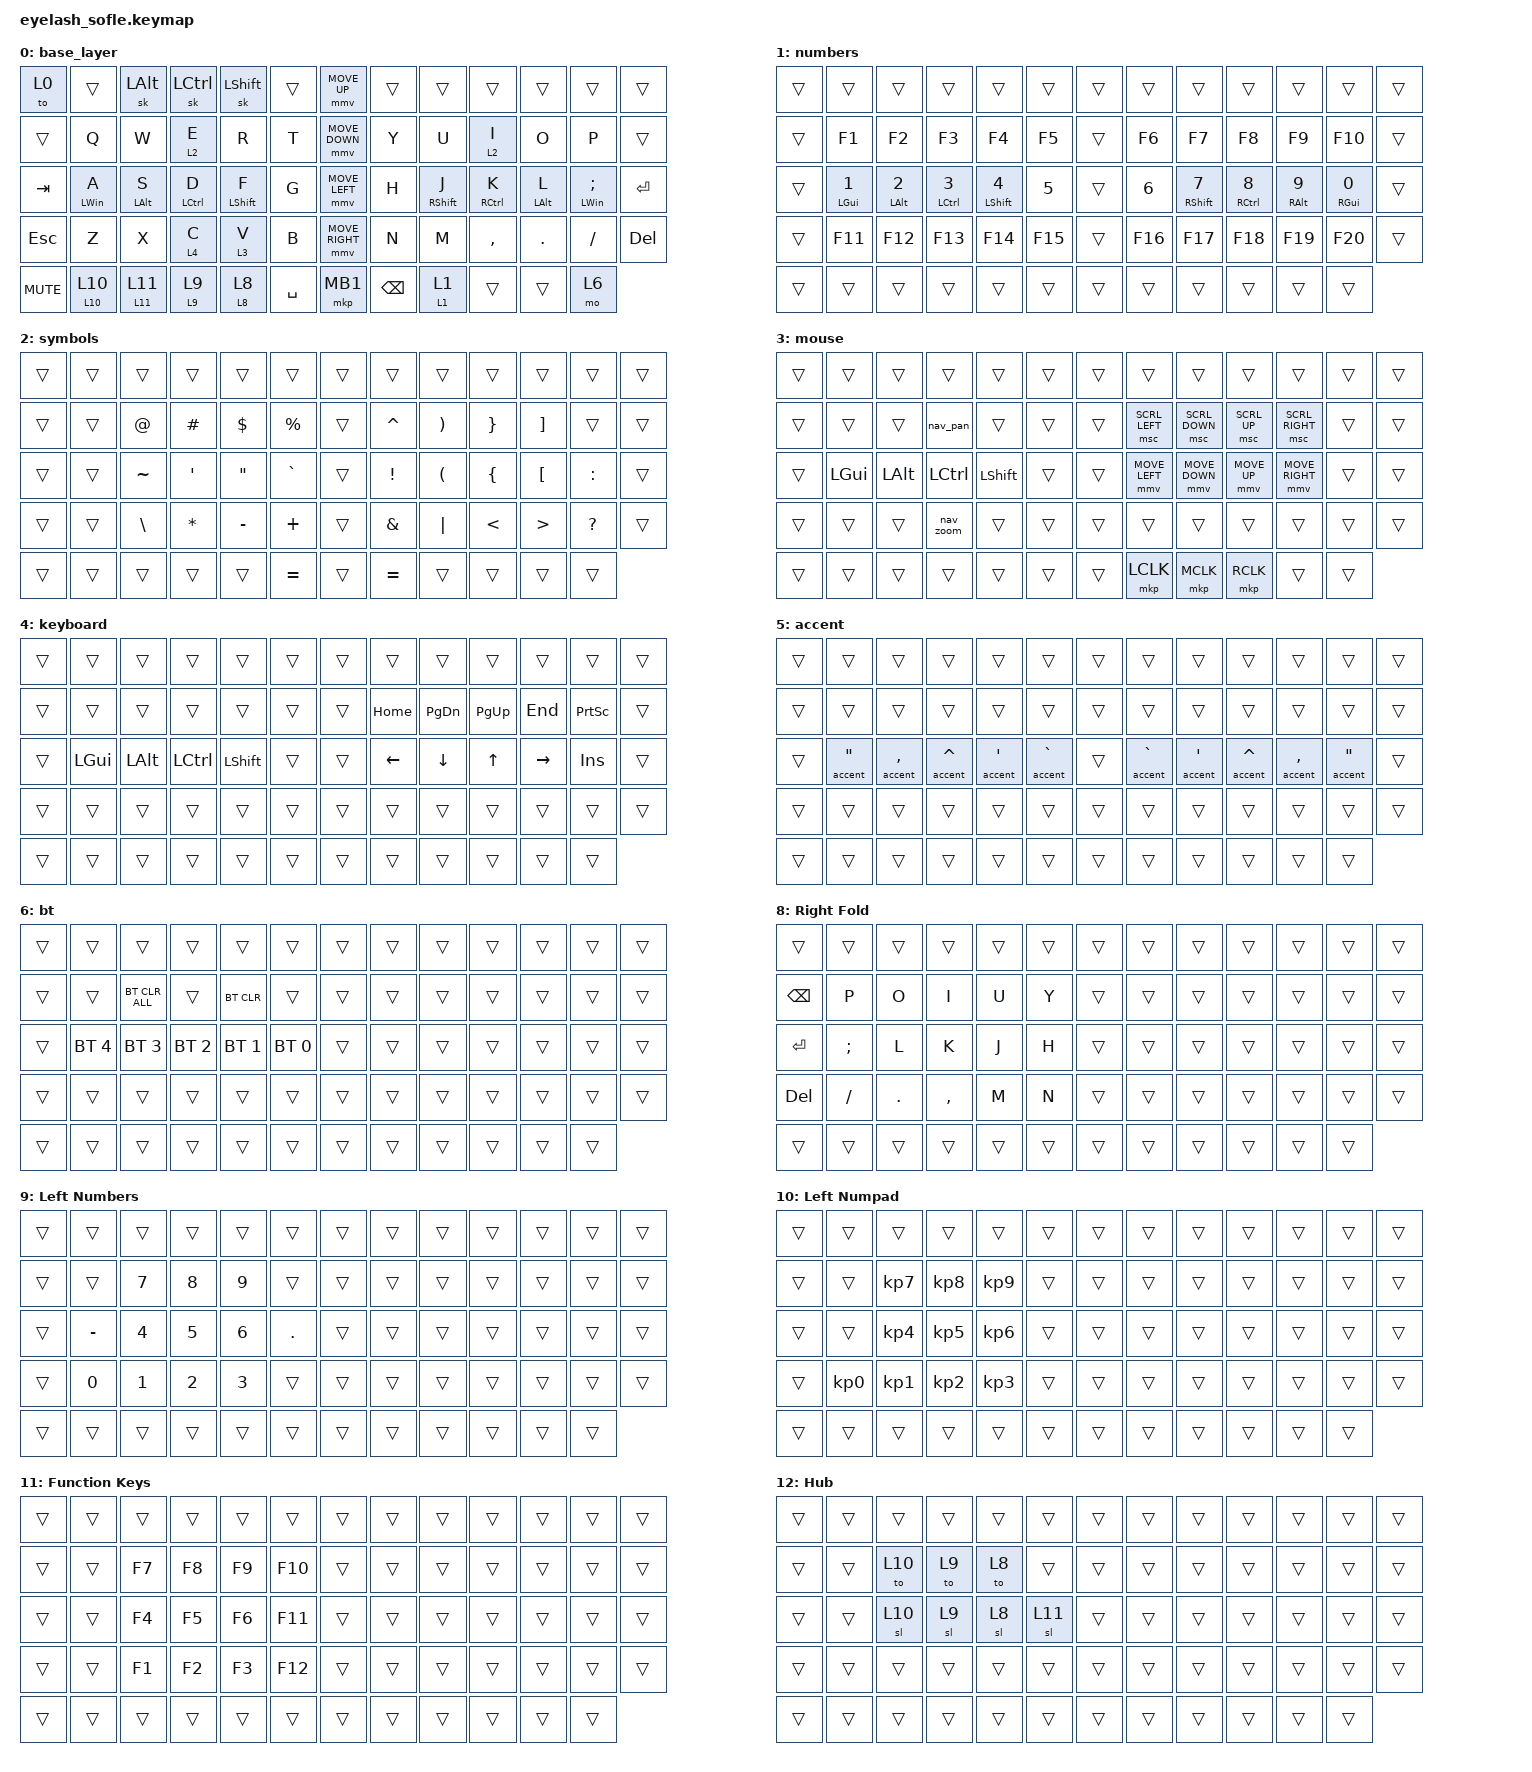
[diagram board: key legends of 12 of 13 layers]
#define ZMK_POINTING_DEFAULT_MOVE_VAL 1200  // 600
#define ZMK_POINTING_DEFAULT_SCRL_VAL 25   // 10

#include <input/processors.dtsi>
#include <zephyr/dt-bindings/input/input-event-codes.h>
#include <behaviors.dtsi>
#include <dt-bindings/zmk/bt.h>
#include <dt-bindings/zmk/keys.h>
#include <dt-bindings/zmk/pointing.h>

&mmv_input_listener { input-processors = <&zip_xy_scaler 2 1>; };

&msc_input_listener { input-processors = <&zip_scroll_scaler 2 1>; };

&msc {
    acceleration-exponent = <1>;      // 0
    time-to-max-speed-ms = <100>;       // 300
    delay-ms = <0>;                   // 0
};

&mmv {
    time-to-max-speed-ms = <500>;
    acceleration-exponent = <1>;
    trigger-period-ms = <16>;
};

&soft_off { hold-time-ms = <2000>; };

/ {
    scroll_encoder: scroll_encoder {
        compatible = "zmk,behavior-sensor-rotate";
        #sensor-binding-cells = <0>;
        bindings = <&msc SCRL_DOWN>, <&msc SCRL_UP>;

        tap-ms = <100>;
    };

    period: period {
        compatible = "zmk,behavior-tap-dance";
        label = "PERIOD";
        #binding-cells = <0>;
        bindings = <&mt EXCL PERIOD>, <&mt QUESTION COLON>;
    };

    period_plus: period_plus {
        compatible = "zmk,behavior-tap-dance";
        label = "PERIOD_PLUS";
        #binding-cells = <0>;
        bindings = <&kp EXCL>, <&kp QMARK>;
    };

    comma: comma {
        compatible = "zmk,behavior-tap-dance";
        label = "COMMA";
        #binding-cells = <0>;
        bindings = <&kp COMMA>, <&kp SEMI>;
    };

    quote: quote {
        compatible = "zmk,behavior-tap-dance";
        label = "QUOTE";
        #binding-cells = <0>;
        bindings = <&mt GRAVE SQT>, <&kp DOUBLE_QUOTES>;
    };

    division: division {
        compatible = "zmk,behavior-tap-dance";
        label = "DIVISION";
        #binding-cells = <0>;
        bindings = <&kp SLASH>, <&kp PERCENT>;
    };

    group_begin: group_begin {
        compatible = "zmk,behavior-tap-dance";
        label = "GROUP_BEGIN";
        #binding-cells = <0>;
        bindings = <&kp LPAR>, <&kp LBKT>, <&kp LBRC>;
    };

    group_end: group_end {
        compatible = "zmk,behavior-tap-dance";
        label = "GROUP_END";
        #binding-cells = <0>;
        bindings = <&kp RPAR>, <&kp RBKT>, <&kp RBRC>;
    };

    encoder_page: encoder_page {
        compatible = "zmk,behavior-sensor-rotate";
        label = "ENCODER_PAGE";
        #sensor-binding-cells = <0>;
        bindings = <&kp PAGE_DOWN>, <&kp PAGE_UP>;
    };

    bt_nav: bt_nav {
        compatible = "zmk,behavior-sensor-rotate";
        label = "BT_NAV";
        #sensor-binding-cells = <0>;
        bindings = <&bt BT_NXT>, <&bt BT_NXT>;
    };

    mouse_mode: mouse_mode {
        compatible = "zmk,behavior-tap-dance";
        label = "MOUSE_MODE";
        #binding-cells = <0>;
        bindings = <&kp M>, <&to 0>;
    };

    keyboard_mode: keyboard_mode {
        compatible = "zmk,behavior-tap-dance";
        label = "KEYBOARD_MODE";
        #binding-cells = <0>;
        bindings = <&kp V>, <&to 0>;
    };

    home_row_mod: home_row_mod {
        compatible = "zmk,behavior-hold-tap";
        label = "HOME_ROW_MOD";
        bindings = <&kp>, <&kp>;

        #binding-cells = <2>;
        tapping-term-ms = <300>;
        flavor = "balanced";
    };

    tap_hold_kp: tap_hold_kp {
        compatible = "zmk,behavior-hold-tap";
        label = "TAP_HOLD_KP";
        bindings = <&kp>, <&kp>;

        #binding-cells = <2>;
        flavor = "tap-preferred";
        tapping-term-ms = <200>;
    };

    sl_or_mo: sl_or_mo {
        compatible = "zmk,behavior-hold-tap";
        label = "SL_OR_MO";
        bindings = <&mo>, <&sl>;

        #binding-cells = <2>;
        tapping-term-ms = <200>;
        flavor = "balanced";
    };

    symbol_layer_access: symbol_layer_access {
        compatible = "zmk,behavior-tap-dance";
        label = "SYMBOL_LAYER_ACCESS";
        #binding-cells = <0>;
        bindings = <&sl_or_mo 0 0>, <&to 0>;
    };

    cedilla_trema: cedilla_trema {
        compatible = "zmk,behavior-hold-tap";
        label = "CEDILLA_TREMA";
        bindings = <&accent>, <&accent>;

        #binding-cells = <2>;
        tapping-term-ms = <200>;
        flavor = "tap-preferred";
    };

    left_hand_dance: left_hand_dance {
        compatible = "zmk,behavior-tap-dance";
        label = "LEFT_HAND_DANCE";
        #binding-cells = <0>;
        bindings = <&mo 0>, <&mo 0>;

        tapping-term-ms = <250>;
    };

    mouse_numbers_dance: mouse_numbers_dance {
        compatible = "zmk,behavior-tap-dance";
        label = "MOUSE_NUMBERS_DANCE";
        #binding-cells = <0>;
        bindings = <&mo 0>, <&mo 0>, <&to 0>;

        tapping-term-ms = <250>;
    };

    caps_constant: caps_constant {
        compatible = "zmk,behavior-caps-word";
        label = "CAPS_CONSTANT";
        #binding-cells = <0>;
        continue-list = <Q W E R T Y U I O P A S D F G H J K L Z X C V B N M UNDERSCORE NUMBER_1 NUMBER_2 NUMBER_3 NUMBER_4 NUMBER_5 NUMBER_6 NUMBER_7 NUMBER_8 NUMBER_9 NUMBER_0 BACKSPACE>;
        mods = <(MOD_LSFT)>;
    };

    sl_to_mo: sl_to_mo {
        compatible = "zmk,behavior-hold-tap";
        label = "SL_TO_MO";
        bindings = <&mo>, <&sl>;

        #binding-cells = <2>;
        tapping-term-ms = <250>;
    };

    kp_or_sk: kp_or_sk {
        compatible = "zmk,behavior-hold-tap";
        label = "KP_OR_SK";
        bindings = <&kp>, <&sk>;

        #binding-cells = <2>;
        tapping-term-ms = <300>;
        flavor = "balanced";
    };

    behaviors {
    };

    combos {
        compatible = "zmk,combos";

        softoff {
            bindings = <&soft_off>;
            key-positions = <14 28 40>;
        };

        combo_accent {
            bindings = <&sl 5>;
            key-positions = <57 59>;
        };

        combo_repeat {
            bindings = <&key_repeat>;
            key-positions = <17 16>;
        };

        combo_mouse_mode {
            bindings = <&to 3>;
            key-positions = <47 48>;
        };

        combo_keyboard_mode {
            bindings = <&to 4>;
            key-positions = <48 49>;
        };

        combo_constant {
            bindings = <&caps_constant>;
            key-positions = <22 23>;
        };

        combo_underscore {
            bindings = <&kp UNDER>;
            key-positions = <21 22>;
        };

        reset {
            bindings = <&to 0>;
            key-positions = <28 29>;
        };

        shift_ctrl {
            bindings = <&sk LS(LCTRL)>;
            key-positions = <4 3>;
        };

        shift_alt {
            bindings = <&sk LS(LEFT_ALT)>;
            key-positions = <4 2>;
        };

        ctrl_alt {
            bindings = <&sk LC(LEFT_ALT)>;
            key-positions = <3 2>;
        };

        shift_ctrl_alt {
            bindings = <&sk LS(LC(LALT))>;
            key-positions = <2 3 4>;
        };

        shift_ctrl_low {
            bindings = <&sk LS(LCTRL)>;
            key-positions = <55 54>;
        };

        shift_alt_low {
            bindings = <&sk LS(LEFT_ALT)>;
            key-positions = <53 55>;
        };

        ctrl_alt_low {
            bindings = <&sk LC(LEFT_ALT)>;
            key-positions = <53 54>;
        };

        shift_ctrl_alt_low {
            bindings = <&sk LS(LC(LALT))>;
            key-positions = <53 54 55>;
        };

        goto_hub {
            bindings = <&sl 12>;
            key-positions = <30 29>;
        };

        combo_constant_left {
            bindings = <&caps_constant>;
            key-positions = <16 15>;
        };
    };

    macros {
        nav_pan: lclk_ctrl {
            compatible = "zmk,behavior-macro";
            #binding-cells = <0>;
            bindings =
                <&macro_press>,
                <&kp LSHFT &mkp MCLK>,
                <&macro_pause_for_release>,
                <&macro_release>,
                <&mkp MCLK &kp LSHFT>;

            label = "LCLK_CTRL";
        };

        nav_zoom: nav_zoom {
            compatible = "zmk,behavior-macro";
            #binding-cells = <0>;
            bindings =
                <&macro_press>,
                <&kp LCTRL &mkp MCLK>,
                <&macro_pause_for_release>,
                <&macro_release>,
                <&mkp MCLK &kp LCTRL>;

            label = "NAV_ZOOM";
        };

        ml_shift: ml_shift {
            compatible = "zmk,behavior-macro";
            #binding-cells = <0>;
            bindings =
                <&macro_press>,
                <&kp LSHFT &mkp LCLK>,
                <&macro_pause_for_release>,
                <&macro_release>,
                <&mkp LCLK &kp LSHFT>;

            label = "ML_SHIFT";
        };

        ml_ctrl: ml_ctrl {
            compatible = "zmk,behavior-macro";
            #binding-cells = <0>;
            bindings =
                <&macro_press>,
                <&kp LCTRL &mkp LCLK>,
                <&macro_pause_for_release>,
                <&macro_release>,
                <&mkp LCLK &kp LCTRL>;

            label = "ML_CTRL";
        };

        ml_alt: ml_alt {
            compatible = "zmk,behavior-macro";
            #binding-cells = <0>;
            bindings =
                <&macro_press>,
                <&kp LALT &mkp LCLK>,
                <&macro_pause_for_release>,
                <&macro_release>,
                <&mkp LCLK &kp LALT>;

            label = "ML_ALT";
        };

        accent: grave_accent {
            compatible = "zmk,behavior-macro-one-param";
            #binding-cells = <1>;
            bindings = <&kp CAPSLOCK &macro_param_1to1 &kp MACRO_PLACEHOLDER>;
            label = "GRAVE_ACCENT";
        };

        new_macro: new_macro {
            compatible = "zmk,behavior-macro-one-param";
            #binding-cells = <1>;
            bindings = <&macro_param_1to1 &sk MACRO_PLACEHOLDER &sl 8>;
            label = "NEW_MACRO";
        };
    };

    keymap {
        compatible = "zmk,keymap";

        base_layer {
            bindings = <
&to 0       &trans                &sk LEFT_ALT          &sk LCTRL              &sk LEFT_SHIFT         &trans       &mmv MOVE_UP     &trans         &trans                  &trans                 &trans                &trans                        &trans
&trans      &kp Q                 &kp W                 &lt 2 E                &kp R                  &kp T        &mmv MOVE_DOWN   &kp Y          &kp U                   &lt 2 I                &kp O                 &kp P                         &trans
&kp TAB     &home_row_mod LWIN A  &home_row_mod LALT S  &home_row_mod LCTRL D  &home_row_mod LSHFT F  &kp G        &mmv MOVE_LEFT   &kp H          &home_row_mod RSHIFT J  &home_row_mod RCTRL K  &home_row_mod LALT L  &home_row_mod LWIN SEMICOLON  &kp ENTER
&kp ESCAPE  &kp Z                 &kp X                 &lt 4 C                &lt 3 V                &kp B        &mmv MOVE_RIGHT  &kp N          &kp M                   &kp COMMA              &kp PERIOD            &kp SLASH                     &kp DELETE
&kp C_MUTE  &sl_or_mo 10 10       &sl_to_mo 11 11       &sl_or_mo 9 9          &sl_or_mo 8 8          &kp SPACE    &mkp MB1         &kp BACKSPACE  &sl_to_mo 1 1           &trans                 &trans                &mo 6
            >;

            display-name = "base_layer";
            sensor-bindings = <&inc_dec_kp PAGE_DOWN PAGE_UP>;
        };

        numbers {
            bindings = <
&trans  &trans                 &trans                 &trans                  &trans                  &trans     &trans  &trans   &trans                  &trans                  &trans                 &trans                 &trans
&trans  &kp F1                 &kp F2                 &kp F3                  &kp F4                  &kp F5     &trans  &kp F6   &kp F7                  &kp F8                  &kp F9                 &kp F10                &trans
&trans  &home_row_mod LGUI N1  &home_row_mod LALT N2  &home_row_mod LCTRL N3  &home_row_mod LSHFT N4  &kp N5     &trans  &kp N6   &home_row_mod RSHFT N7  &home_row_mod RCTRL N8  &home_row_mod RALT N9  &home_row_mod RGUI N0  &trans
&trans  &kp F11                &kp F12                &kp F13                 &kp F14                 &kp F15    &trans  &kp F16  &kp F17                 &kp F18                 &kp F19                &kp F20                &trans
&trans  &trans                 &trans                 &trans                  &trans                  &trans     &trans  &trans   &trans                  &trans                  &trans                 &trans
            >;

            label = "numbers";
        };

        symbols {
            label = "symbols";
            bindings = <
&trans  &trans  &trans         &trans    &trans      &trans         &trans  &trans           &trans    &trans    &trans    &trans        &trans
&trans  &trans  &kp AT         &kp HASH  &kp DOLLAR  &kp PERCENT    &trans  &kp CARET        &kp RPAR  &kp RBRC  &kp RBKT  &trans        &trans
&trans  &trans  &kp TILDE      &kp SQT   &kp DQT     &kp GRAVE      &trans  &kp EXCLAMATION  &kp LPAR  &kp LBRC  &kp LBKT  &kp COLON     &trans
&trans  &trans  &kp BACKSLASH  &kp STAR  &kp MINUS   &kp PLUS       &trans  &kp AMPS         &kp PIPE  &kp LT    &kp GT    &kp QUESTION  &trans
&trans  &trans  &trans         &trans    &trans      &kp EQUAL      &trans  &kp EQUAL        &trans    &trans    &trans    &trans
            >;
        };

        mouse {
            bindings = <
&trans  &trans    &trans    &trans     &trans     &trans    &trans  &trans          &trans          &trans        &trans           &trans  &trans
&trans  &trans    &trans    &nav_pan   &trans     &trans    &trans  &msc SCRL_LEFT  &msc SCRL_DOWN  &msc SCRL_UP  &msc SCRL_RIGHT  &trans  &trans
&trans  &kp LGUI  &kp LALT  &kp LCTRL  &kp LSHFT  &trans    &trans  &mmv MOVE_LEFT  &mmv MOVE_DOWN  &mmv MOVE_UP  &mmv MOVE_RIGHT  &trans  &trans
&trans  &trans    &trans    &nav_zoom  &trans     &trans    &trans  &trans          &trans          &trans        &trans           &trans  &trans
&trans  &trans    &trans    &trans     &trans     &trans    &trans  &mkp LCLK       &mkp MCLK       &mkp RCLK     &trans           &trans
            >;

            label = "mouse";
        };

        keyboard {
            bindings = <
&trans  &trans    &trans    &trans     &trans     &trans    &trans  &trans    &trans         &trans       &trans     &trans           &trans
&trans  &trans    &trans    &trans     &trans     &trans    &trans  &kp HOME  &kp PAGE_DOWN  &kp PAGE_UP  &kp END    &kp PRINTSCREEN  &trans
&trans  &kp LGUI  &kp LALT  &kp LCTRL  &kp LSHFT  &trans    &trans  &kp LEFT  &kp DOWN       &kp UP       &kp RIGHT  &kp INSERT       &trans
&trans  &trans    &trans    &trans     &trans     &trans    &trans  &trans    &trans         &trans       &trans     &trans           &trans
&trans  &trans    &trans    &trans     &trans     &trans    &trans  &trans    &trans         &trans       &trans     &trans
            >;

            label = "keyboard";
        };

        accent {
            bindings = <
&trans  &trans                 &trans         &trans         &trans       &trans           &trans  &trans         &trans        &trans         &trans         &trans                 &trans
&trans  &trans                 &trans         &trans         &trans       &trans           &trans  &trans         &trans        &trans         &trans         &trans                 &trans
&trans  &accent DOUBLE_QUOTES  &accent COMMA  &accent CARET  &accent SQT  &accent GRAVE    &trans  &accent GRAVE  &accent APOS  &accent CARET  &accent COMMA  &accent DOUBLE_QUOTES  &trans
&trans  &trans                 &trans         &trans         &trans       &trans           &trans  &trans         &trans        &trans         &trans         &trans                 &trans
&trans  &trans                 &trans         &trans         &trans       &trans           &trans  &trans         &trans        &trans         &trans         &trans
            >;

            label = "accent";
        };

        bt {
            bindings = <
&trans  &trans        &trans          &trans        &trans        &trans          &trans  &trans  &trans  &trans  &trans  &trans  &trans
&trans  &trans        &bt BT_CLR_ALL  &trans        &bt BT_CLR    &trans          &trans  &trans  &trans  &trans  &trans  &trans  &trans
&trans  &bt BT_SEL 4  &bt BT_SEL 3    &bt BT_SEL 2  &bt BT_SEL 1  &bt BT_SEL 0    &trans  &trans  &trans  &trans  &trans  &trans  &trans
&trans  &trans        &trans          &trans        &trans        &trans          &trans  &trans  &trans  &trans  &trans  &trans  &trans
&trans  &trans        &trans          &trans        &trans        &trans          &trans  &trans  &trans  &trans  &trans  &trans
            >;

            label = "bt";
        };

        shortcut {
            bindings = <
&trans  &trans                 &trans                 &trans                 &trans                 &trans                   &trans  &trans                 &trans                 &trans                  &trans                  &trans                     &trans
&trans  &kp LS(LG(LC(LA(Q))))  &kp LS(LG(LC(LA(W))))  &kp LS(LG(LC(LA(E))))  &kp LS(LG(LC(LA(R))))  &kp LS(LG(LC(LA(T))))    &trans  &kp LS(LG(LC(LA(Y))))  &kp LS(LG(LC(LA(U))))  &kp LS(LG(LC(LA(I))))   &kp LS(LG(LC(LA(O))))   &kp LS(LG(LC(LA(P))))      &trans
&trans  &kp LS(LG(LC(LA(A))))  &kp LS(LG(LC(LA(S))))  &kp LS(LG(LC(LA(D))))  &kp LS(LG(LC(LA(F))))  &kp LS(LG(LC(LA(G))))    &trans  &kp LS(LG(LC(LA(H))))  &kp LS(LG(LC(LA(J))))  &kp LS(LG(LC(LA(K))))   &kp LS(LG(LC(LA(L))))   &kp LS(LG(LC(LA(COLON))))  &trans
&trans  &kp LS(LG(LC(LA(Z))))  &kp LS(LG(LC(LA(X))))  &kp LS(LG(LC(LA(C))))  &kp LS(LG(LC(LA(V))))  &kp LS(LG(LC(LA(B))))    &trans  &kp LS(LG(LC(LA(N))))  &kp LS(LG(LC(LA(M))))  &kp LS(LG(LC(LA(LT))))  &kp LS(LG(LC(LA(GT))))  &kp LS(LG(LC(LA(QMARK))))  &trans
&trans  &trans                 &trans                 &trans                 &trans                 &trans                   &trans  &trans                 &trans                 &trans                  &trans                  &trans
            >;

            label = "shortcut";
        };

        right_fold {
            bindings = <
&trans         &trans    &trans   &trans     &trans  &trans    &trans  &trans  &trans  &trans  &trans  &trans  &trans
&kp BACKSPACE  &kp P     &kp O    &kp I      &kp U   &kp Y     &trans  &trans  &trans  &trans  &trans  &trans  &trans
&kp ENTER      &kp SEMI  &kp L    &kp K      &kp J   &kp H     &trans  &trans  &trans  &trans  &trans  &trans  &trans
&kp DELETE     &kp FSLH  &kp DOT  &kp COMMA  &kp M   &kp N     &trans  &trans  &trans  &trans  &trans  &trans  &trans
&trans         &trans    &trans   &trans     &trans  &trans    &trans  &trans  &trans  &trans  &trans  &trans
            >;

            label = "Right Fold";
        };

        left_numbers {
            bindings = <
&trans  &trans     &trans  &trans  &trans  &trans        &trans  &trans  &trans  &trans  &trans  &trans  &trans
&trans  &trans     &kp N7  &kp N8  &kp N9  &trans        &trans  &trans  &trans  &trans  &trans  &trans  &trans
&trans  &kp MINUS  &kp N4  &kp N5  &kp N6  &kp PERIOD    &trans  &trans  &trans  &trans  &trans  &trans  &trans
&trans  &kp N0     &kp N1  &kp N2  &kp N3  &trans        &trans  &trans  &trans  &trans  &trans  &trans  &trans
&trans  &trans     &trans  &trans  &trans  &trans        &trans  &trans  &trans  &trans  &trans  &trans
            >;

            label = "Left Numbers";
        };

        left_numpad {
            bindings = <
&trans  &trans     &trans           &trans           &trans           &trans    &trans  &trans  &trans  &trans  &trans  &trans  &trans
&trans  &trans     &kp KP_NUMBER_7  &kp KP_NUMBER_8  &kp KP_NUMBER_9  &trans    &trans  &trans  &trans  &trans  &trans  &trans  &trans
&trans  &trans     &kp KP_NUMBER_4  &kp KP_NUMBER_5  &kp KP_NUMBER_6  &trans    &trans  &trans  &trans  &trans  &trans  &trans  &trans
&trans  &kp KP_N0  &kp KP_NUMBER_1  &kp KP_NUMBER_2  &kp KP_NUMBER_3  &trans    &trans  &trans  &trans  &trans  &trans  &trans  &trans
&trans  &trans     &trans           &trans           &trans           &trans    &trans  &trans  &trans  &trans  &trans  &trans
            >;

            label = "Left Numpad";
        };

        function_keys {
            bindings = <
&trans  &trans  &trans  &trans  &trans  &trans     &trans  &trans  &trans  &trans  &trans  &trans  &trans
&trans  &trans  &kp F7  &kp F8  &kp F9  &kp F10    &trans  &trans  &trans  &trans  &trans  &trans  &trans
&trans  &trans  &kp F4  &kp F5  &kp F6  &kp F11    &trans  &trans  &trans  &trans  &trans  &trans  &trans
&trans  &trans  &kp F1  &kp F2  &kp F3  &kp F12    &trans  &trans  &trans  &trans  &trans  &trans  &trans
&trans  &trans  &trans  &trans  &trans  &trans     &trans  &trans  &trans  &trans  &trans  &trans
            >;

            label = "Function Keys";
        };

        hub {
            bindings = <
&trans  &trans  &trans  &trans  &trans  &trans    &trans  &trans  &trans  &trans  &trans  &trans  &trans
&trans  &trans  &to 10  &to 9   &to 8   &trans    &trans  &trans  &trans  &trans  &trans  &trans  &trans
&trans  &trans  &sl 10  &sl 9   &sl 8   &sl 11    &trans  &trans  &trans  &trans  &trans  &trans  &trans
&trans  &trans  &trans  &trans  &trans  &trans    &trans  &trans  &trans  &trans  &trans  &trans  &trans
&trans  &trans  &trans  &trans  &trans  &trans    &trans  &trans  &trans  &trans  &trans  &trans
            >;

            label = "Hub";
        };
    };
};
